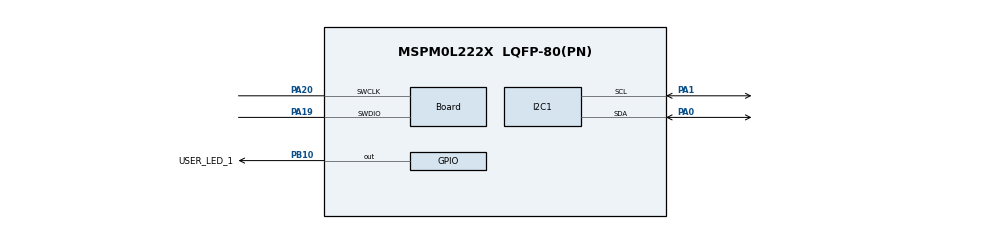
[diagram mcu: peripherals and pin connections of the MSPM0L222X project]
// @cliArgs --device "MSPM0L222X" --package "LQFP-80(PN)" --part "Default"
// @cliArgs --board /ti/boards/LP_MSPM0L2228 --rtos nortos

/**
 * Import the modules used in this configuration.
 */
const Board = scripting.addModule("/ti/driverlib/Board");
const GPIO  = scripting.addModule("/ti/driverlib/GPIO", {}, false);
const GPIO1 = GPIO.addInstance();
const I2C   = scripting.addModule("/ti/driverlib/I2C", {}, false);
const I2C1  = I2C.addInstance();

/**
 * Write custom configuration values to the imported modules.
 */
Board.peripheral.$assign          = "DEBUGSS";
Board.peripheral.swclkPin.$assign = "PA20";
Board.peripheral.swdioPin.$assign = "PA19";

GPIO1.$name                                 = "GPIO_LEDS";
GPIO1.associatedPins[0].$name               = "USER_LED_1";
GPIO1.associatedPins[0].initialValue        = "CLEARED";
GPIO1.associatedPins[0].pin.$assign         = "PB10";

I2C1.$name                     = "I2C";
I2C1.basicControllerBusSpeed   = 400000;
I2C1.advControllerTXFIFOTRIG   = "BYTES_1";
I2C1.advTargetTXFIFOTRIG       = "BYTES_1";
I2C1.basicTargetAddress        = 0x48;
I2C1.basicEnableTarget         = true;
I2C1.intTarget                 = ["RXFIFO_TRIGGER","START","STOP"];
I2C1.advAnalogGlitchFilter     = "DISABLED";
I2C1.advTargetTXEmptyEn        = true;
I2C1.peripheral.$assign        = "I2C0";
I2C1.peripheral.sdaPin.$assign = "PA0";
I2C1.peripheral.sclPin.$assign = "PA1";

const SYSCTL              = scripting.addModule("/ti/driverlib/SYSCTL", {}, false);
SYSCTL.peripheral.$assign = "SYSCTL";
SYSCTL.clockTreeEn = true;
